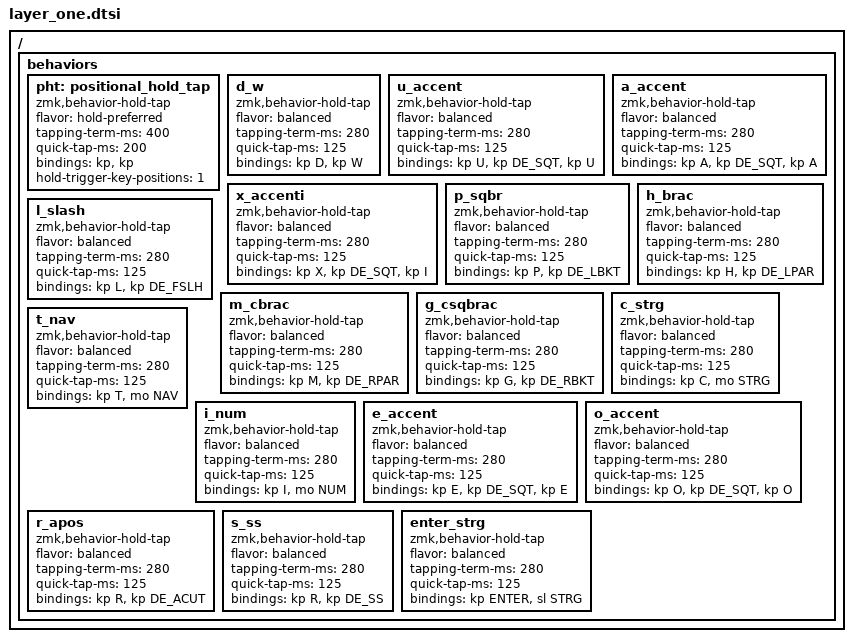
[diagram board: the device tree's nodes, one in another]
/ {
    behaviors {
        pht: positional_hold_tap {
            compatible = "zmk,behavior-hold-tap";
            #binding-cells = <2>;
            flavor = "hold-preferred";
            tapping-term-ms = <400>;
            quick-tap-ms = <200>;
            bindings = <&kp>, <&kp>;
            hold-trigger-key-positions = <1>;    // <---[[the W key]]
        };

        d_w: d_w {
            compatible = "zmk,behavior-hold-tap";
            #binding-cells = <2>;
            flavor = "balanced";
            tapping-term-ms = <280>;
            quick-tap-ms = <125>;
            bindings = <&kp D>, <&kp W>;
        };

        u_accent: u_accent {
            compatible = "zmk,behavior-hold-tap";
            #binding-cells = <2>;
            flavor = "balanced";
            tapping-term-ms = <280>;
            quick-tap-ms = <125>;
            bindings = <&kp U>, <&kp DE_SQT &kp U>;
        };

        a_accent: a_accent {
            compatible = "zmk,behavior-hold-tap";
            #binding-cells = <2>;
            flavor = "balanced";
            tapping-term-ms = <280>;
            quick-tap-ms = <125>;
            bindings = <&kp A>, <&kp DE_SQT &kp A>;
        };

        x_accenti: x_accenti {
            compatible = "zmk,behavior-hold-tap";
            #binding-cells = <2>;
            flavor = "balanced";
            tapping-term-ms = <280>;
            quick-tap-ms = <125>;
            bindings = <&kp X>, <&kp DE_SQT &kp I>;
        };

        p_sqbr: p_sqbr {
            compatible = "zmk,behavior-hold-tap";
            #binding-cells = <2>;
            flavor = "balanced";
            tapping-term-ms = <280>;
            quick-tap-ms = <125>;
            bindings = <&kp P>, <&kp DE_LBKT>;
        };

        h_brac: h_brac {
            compatible = "zmk,behavior-hold-tap";
            #binding-cells = <2>;
            flavor = "balanced";
            tapping-term-ms = <280>;
            quick-tap-ms = <125>;
            bindings = <&kp H>, <&kp DE_LPAR>;
        };

        l_slash: l_slash {
            compatible = "zmk,behavior-hold-tap";
            #binding-cells = <2>;
            flavor = "balanced";
            tapping-term-ms = <280>;
            quick-tap-ms = <125>;
            bindings = <&kp L>, <&kp DE_FSLH>;
        };

        m_cbrac: m_cbrac {
            compatible = "zmk,behavior-hold-tap";
            #binding-cells = <2>;
            flavor = "balanced";
            tapping-term-ms = <280>;
            quick-tap-ms = <125>;
            bindings = <&kp M>, <&kp DE_RPAR>;
        };

        g_csqbrac: g_csqbrac {
            compatible = "zmk,behavior-hold-tap";
            #binding-cells = <2>;
            flavor = "balanced";
            tapping-term-ms = <280>;
            quick-tap-ms = <125>;
            bindings = <&kp G>, <&kp DE_RBKT>;
        };

        c_strg: c_strg {
            compatible = "zmk,behavior-hold-tap";
            #binding-cells = <2>;
            flavor = "balanced";
            tapping-term-ms = <280>;
            quick-tap-ms = <125>;
         bindings = <&kp C>, <&mo STRG>;
        };

        t_nav: t_nav {
            compatible = "zmk,behavior-hold-tap";
            #binding-cells = <2>;
            flavor = "balanced";
            tapping-term-ms = <280>;
            quick-tap-ms = <125>;
            bindings = <&kp T>, <&mo NAV>;
        };

        i_num: i_num {
            compatible = "zmk,behavior-hold-tap";
            #binding-cells = <2>;
            flavor = "balanced";
            tapping-term-ms = <280>;
            quick-tap-ms = <125>;
            bindings = <&kp I>, <&mo NUM>;
        };

        e_accent: e_accent {
            compatible = "zmk,behavior-hold-tap";
            #binding-cells = <2>;
            flavor = "balanced";
            tapping-term-ms = <280>;
            quick-tap-ms = <125>;
            bindings = <&kp E>, <&kp DE_SQT &kp E>;
        };

        o_accent: o_accent {
            compatible = "zmk,behavior-hold-tap";
            #binding-cells = <2>;
            flavor = "balanced";
            tapping-term-ms = <280>;
            quick-tap-ms = <125>;
            bindings = <&kp O>, <&kp DE_SQT &kp O>;
        };

        r_apos: r_apos {
            compatible = "zmk,behavior-hold-tap";
            #binding-cells = <2>;
            flavor = "balanced";
            tapping-term-ms = <280>;
            quick-tap-ms = <125>;
            bindings = <&kp R>, <&kp DE_ACUT>;
        };

        s_ss: s_ss {
            compatible = "zmk,behavior-hold-tap";
            #binding-cells = <2>;
            flavor = "balanced";
            tapping-term-ms = <280>;
            quick-tap-ms = <125>;
            bindings = <&kp R>, <&kp DE_SS>;
        };

        enter_strg: enter_strg {
            compatible = "zmk,behavior-hold-tap";
            #binding-cells = <2>;
            flavor = "balanced";
            tapping-term-ms = <280>;
            quick-tap-ms = <125>;
            bindings = <&kp ENTER>, <&sl STRG>;
        };
    };
};


/*ZMK_BEHAVIOR(udia_accent, hold_tap,
    flavor = "balanced";
    tapping-term-ms = <280>;
    quick-tap-ms = <125>;
    bindings = <&kp DE_UDIA>, <&udiaaccent>;
)

ZMK_BEHAVIOR(udiaaccent, macro,
    bindings = <&macro_press &kp LALT>, <&macro_tap &kp KP_N0 &kp KP_N3 &kp KP_N6 &kp KP_N9>, <&macro_release &kp LALT>;
)

ZMK_BEHAVIOR(odia_accent, hold_tap,
    flavor = "balanced";
    tapping-term-ms = <280>;
    quick-tap-ms = <125>;
    bindings = <&kp DE_ODIA>, <&odiaaccent>;
)

ZMK_BEHAVIOR(odiaaccent, macro,
    bindings = <&macro_press &kp LALT>, <&macro_tap &kp KP_N0 &kp KP_N3 &kp KP_N3 &kp KP_N7>, <&macro_release &kp LALT>;
)

ZMK_BEHAVIOR(td_z_at, tap_dance,
    tapping-term-ms = <250>;
    bindings = <&kp DE_Z>, <&kp DE_AT>;
)

ZMK_BEHAVIOR(td_comm_quest, tap_dance,
    tapping-term-ms = <250>;
    bindings = <&kp DE_COMM>, <&kp DE_QUES>;
)

ZMK_BEHAVIOR(k_q, hold_tap,
    flavor = "balanced";
    tapping-term-ms = <280>;
    quick-tap-ms = <125>;
    bindings = <&kp K>, <&kp Q>;
)

ZMK_BEHAVIOR(dot_excl, hold_tap,
    flavor = "balanced";
    tapping-term-ms = <280>;
    quick-tap-ms = <125>;
    bindings = <&kp DE_DOT>, <&kp DE_EXCL>;
)

ZMK_BEHAVIOR(space_nav, hold_tap,
    flavor = "balanced";
    tapping-term-ms = <280>;
    quick-tap-ms = <125>;
    bindings = <&kp SPACE>, <&mo NAV>;
)*/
